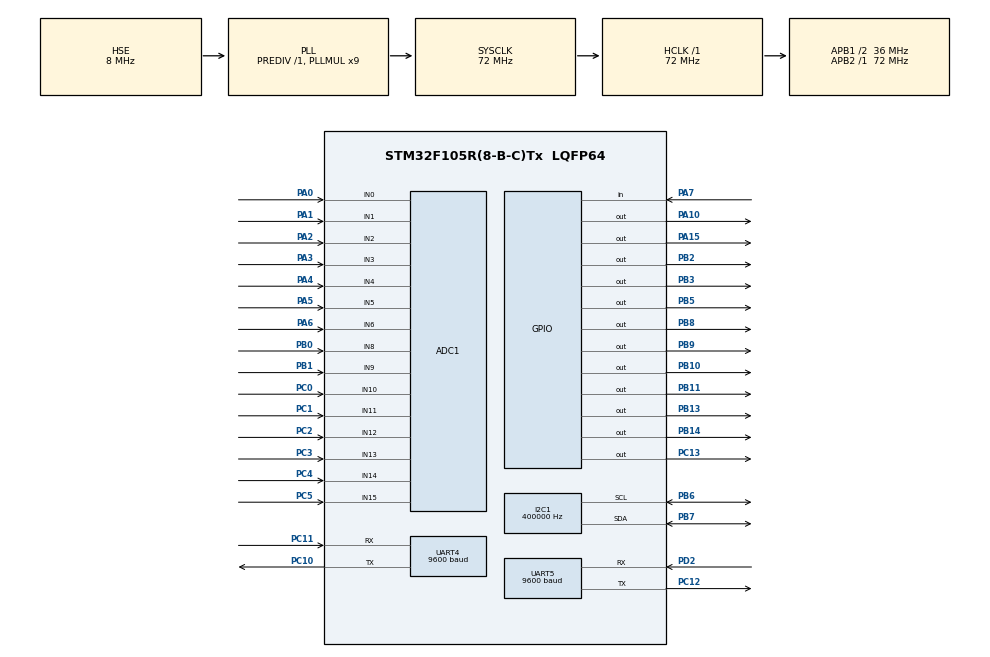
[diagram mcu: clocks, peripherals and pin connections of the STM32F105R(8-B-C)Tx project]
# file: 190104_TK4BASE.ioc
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ADC1.Channel-0\#ChannelRegularConversion=ADC_CHANNEL_0
ADC1.Channel-1\#ChannelRegularConversion=ADC_CHANNEL_1
ADC1.Channel-2\#ChannelRegularConversion=ADC_CHANNEL_2
ADC1.Channel-3\#ChannelRegularConversion=ADC_CHANNEL_3
ADC1.Channel-4\#ChannelRegularConversion=ADC_CHANNEL_4
ADC1.Channel-5\#ChannelRegularConversion=ADC_CHANNEL_5
ADC1.InjNumberOfConversion=0
ADC1.NbrOfConversion=6
ADC1.NbrOfConversionFlag=1
ADC1.Rank-0\#ChannelRegularConversion=1
ADC1.Rank-1\#ChannelRegularConversion=2
ADC1.Rank-2\#ChannelRegularConversion=3
ADC1.Rank-3\#ChannelRegularConversion=4
ADC1.Rank-4\#ChannelRegularConversion=5
ADC1.Rank-5\#ChannelRegularConversion=6
ADC1.SamplingTime-0\#ChannelRegularConversion=ADC_SAMPLETIME_1CYCLE_5
ADC1.SamplingTime-1\#ChannelRegularConversion=ADC_SAMPLETIME_1CYCLE_5
ADC1.SamplingTime-2\#ChannelRegularConversion=ADC_SAMPLETIME_1CYCLE_5
ADC1.SamplingTime-3\#ChannelRegularConversion=ADC_SAMPLETIME_1CYCLE_5
ADC1.SamplingTime-4\#ChannelRegularConversion=ADC_SAMPLETIME_1CYCLE_5
ADC1.SamplingTime-5\#ChannelRegularConversion=ADC_SAMPLETIME_1CYCLE_5
ADC1.master=1
Dma.ADC1.0.Direction=DMA_PERIPH_TO_MEMORY
Dma.ADC1.0.Instance=DMA1_Channel1
Dma.ADC1.0.MemDataAlignment=DMA_MDATAALIGN_HALFWORD
Dma.ADC1.0.MemInc=DMA_MINC_ENABLE
Dma.ADC1.0.Mode=DMA_NORMAL
Dma.ADC1.0.PeriphDataAlignment=DMA_PDATAALIGN_HALFWORD
Dma.ADC1.0.PeriphInc=DMA_PINC_DISABLE
Dma.ADC1.0.Priority=DMA_PRIORITY_LOW
Dma.Request0=ADC1
I2C1.ClockSpeed=400000
I2C1.I2C_Mode=I2C_Fast
Mcu.Family=STM32F1
Mcu.Name=STM32F105R(8-B-C)Tx
Mcu.Package=LQFP64
NVIC.DMA1_Channel1_IRQn=true\:0\:0\:false\:false\:true\:false
NVIC.PriorityGroup=NVIC_PRIORITYGROUP_4
NVIC.TIM6_IRQn=true\:0\:0\:false\:false\:true\:true
NVIC.TIM7_IRQn=true\:0\:0\:false\:false\:true\:true
NVIC.UART4_IRQn=true\:0\:0\:false\:false\:true\:true
NVIC.UART5_IRQn=true\:0\:0\:false\:false\:true\:true
PA0-WKUP.Signal=ADCx_IN0
PA1.Signal=ADCx_IN1
PA10.GPIO_ModeDefaultOutputPP=GPIO_MODE_OUTPUT_PP
PA10.GPIO_Speed=GPIO_SPEED_FREQ_LOW
PA10.PinState=GPIO_PIN_RESET
PA10.Signal=GPIO_Output
PA13.Mode=Serial_Wire
PA13.Signal=SYS_JTMS-SWDIO
PA14.Mode=Serial_Wire
PA14.Signal=SYS_JTCK-SWCLK
PA15.Signal=GPIO_Output
PA2.Signal=ADCx_IN2
PA3.Signal=ADCx_IN3
PA4.Signal=ADCx_IN4
PA5.Signal=ADCx_IN5
PA6.Signal=ADCx_IN6
PA7.Signal=GPIO_Input
PB0.Signal=ADCx_IN8
PB1.Signal=ADCx_IN9
PB10.GPIO_ModeDefaultOutputPP=GPIO_MODE_OUTPUT_PP
PB10.GPIO_Speed=GPIO_SPEED_FREQ_LOW
PB10.PinState=GPIO_PIN_RESET
PB10.Signal=GPIO_Output
PB11.GPIO_ModeDefaultOutputPP=GPIO_MODE_OUTPUT_PP
PB11.GPIO_Speed=GPIO_SPEED_FREQ_LOW
PB11.PinState=GPIO_PIN_RESET
PB11.Signal=GPIO_Output
PB13.Signal=GPIO_Output
PB14.Signal=GPIO_Output
PB2.GPIO_ModeDefaultOutputPP=GPIO_MODE_OUTPUT_PP
PB2.GPIO_Speed=GPIO_SPEED_FREQ_LOW
PB2.PinState=GPIO_PIN_RESET
PB2.Signal=GPIO_Output
PB3.Signal=GPIO_Output
PB5.Signal=GPIO_Output
PB6.GPIO_Mode=GPIO_MODE_AF_OD
PB6.GPIO_Speed=GPIO_SPEED_FREQ_HIGH
PB6.Mode=I2C
PB6.Signal=I2C1_SCL
PB7.GPIO_Mode=GPIO_MODE_AF_OD
PB7.GPIO_Speed=GPIO_SPEED_FREQ_HIGH
PB7.Mode=I2C
PB7.Signal=I2C1_SDA
PB8.Signal=GPIO_Output
PB9.Signal=GPIO_Output
PC0.Signal=ADCx_IN10
PC1.Signal=ADCx_IN11
PC10.Mode=Asynchronous
PC10.Signal=UART4_TX
PC11.Mode=Asynchronous
PC11.Signal=UART4_RX
PC12.Mode=Asynchronous
PC12.Signal=UART5_TX
PC13-TAMPER-RTC.GPIO_ModeDefaultOutputPP=GPIO_MODE_OUTPUT_PP
PC13-TAMPER-RTC.GPIO_Speed=GPIO_SPEED_FREQ_LOW
PC13-TAMPER-RTC.PinState=GPIO_PIN_RESET
PC13-TAMPER-RTC.Signal=GPIO_Output
PC14-OSC32_IN.Mode=LSE-External-Oscillator
PC14-OSC32_IN.Signal=RCC_OSC32_IN
PC15-OSC32_OUT.Mode=LSE-External-Oscillator
PC15-OSC32_OUT.Signal=RCC_OSC32_OUT
PC2.Signal=ADCx_IN12
PC3.Signal=ADCx_IN13
PC4.Signal=ADCx_IN14
PC5.Signal=ADCx_IN15
PD0-OSC_IN.Mode=HSE-External-Oscillator
PD0-OSC_IN.Signal=RCC_OSC_IN
PD1-OSC_OUT.Mode=HSE-External-Oscillator
PD1-OSC_OUT.Signal=RCC_OSC_OUT
PD2.Mode=Asynchronous
PD2.Signal=UART5_RX
ProjectManager.HeapSize=0x200
ProjectManager.StackSize=0x400
ProjectManager.TargetToolchain=SW4STM32
RCC.ADCPresc=RCC_ADCPCLK2_DIV6
RCC.AHBFreq_Value=72000000
RCC.APB1CLKDivider=RCC_HCLK_DIV2
RCC.APB1Freq_Value=36000000
RCC.APB1TimFreq_Value=72000000
RCC.APB2Freq_Value=72000000
RCC.APB2TimFreq_Value=72000000
RCC.HCLKFreq_Value=72000000
RCC.PLL2Mul=RCC_PLL2_MUL10
RCC.PLLMUL=RCC_PLL_MUL9
RCC.PLLSourceVirtual=RCC_PLLSOURCE_HSE
RCC.Prediv2=RCC_HSE_PREDIV2_DIV2
RCC.RTCClockSelection=RCC_RTCCLKSOURCE_LSE
RCC.SYSCLKFreq_VALUE=72000000
RCC.SYSCLKSource=RCC_SYSCLKSOURCE_PLLCLK
RCC.USBFreq_Value=48000000
SH.ADCx_IN0.0=ADC1_IN0,IN0
SH.ADCx_IN1.0=ADC1_IN1,IN1
SH.ADCx_IN10.0=ADC1_IN10,IN10
SH.ADCx_IN11.0=ADC1_IN11,IN11
SH.ADCx_IN12.0=ADC1_IN12,IN12
SH.ADCx_IN13.0=ADC1_IN13,IN13
SH.ADCx_IN14.0=ADC1_IN14,IN14
SH.ADCx_IN15.0=ADC1_IN15,IN15
SH.ADCx_IN2.0=ADC1_IN2,IN2
SH.ADCx_IN3.0=ADC1_IN3,IN3
SH.ADCx_IN4.0=ADC1_IN4,IN4
SH.ADCx_IN5.0=ADC1_IN5,IN5
SH.ADCx_IN6.0=ADC1_IN6,IN6
SH.ADCx_IN8.0=ADC1_IN8,IN8
SH.ADCx_IN9.0=ADC1_IN9,IN9
TIM6.Prescaler=7200-1
TIM7.Prescaler=7200-1
UART4.BaudRate=9600
UART4.VirtualMode=Asynchronous
UART4.WordLength=WORDLENGTH_8B
UART5.BaudRate=9600
UART5.VirtualMode=Asynchronous
UART5.WordLength=WORDLENGTH_8B
VP_CRC_VS_CRC.Mode=CRC_Activate
VP_IWDG_VS_IWDG.Mode=IWDG_Activate
VP_RTC_VS_RTC_Activate.Mode=RTC_Enabled
VP_RTC_VS_RTC_Calendar.Mode=RTC_Calendar
VP_TIM6_VS_ClockSourceINT.Mode=Enable_Timer
VP_TIM7_VS_ClockSourceINT.Mode=Enable_Timer
board=171108_test

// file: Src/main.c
/* USER CODE BEGIN Header */
/**
  ******************************************************************************
  * @file           : main.c
  * @brief          : Main program body
  ******************************************************************************
  ** This notice applies to any and all portions of this file
  * that are not between comment pairs USER CODE BEGIN and
  * USER CODE END. Other portions of this file, whether
  * inserted by the user or by software development tools
  * are owned by their respective copyright owners.
  *
  * COPYRIGHT(c) 2019 STMicroelectronics
  *
  * Redistribution and use in source and binary forms, with or without modification,
  * are permitted provided that the following conditions are met:
  *   1. Redistributions of source code must retain the above copyright notice,
  *      this list of conditions and the following disclaimer.
  *   2. Redistributions in binary form must reproduce the above copyright notice,
  *      this list of conditions and the following disclaimer in the documentation
  *      and/or other materials provided with the distribution.
  *   3. Neither the name of STMicroelectronics nor the names of its contributors
  *      may be used to endorse or promote products derived from this software
  *      without specific prior written permission.
  *
  * THIS SOFTWARE IS PROVIDED BY THE COPYRIGHT HOLDERS AND CONTRIBUTORS "AS IS"
  * AND ANY EXPRESS OR IMPLIED WARRANTIES, INCLUDING, BUT NOT LIMITED TO, THE
  * IMPLIED WARRANTIES OF MERCHANTABILITY AND FITNESS FOR A PARTICULAR PURPOSE ARE
  * DISCLAIMED. IN NO EVENT SHALL THE COPYRIGHT HOLDER OR CONTRIBUTORS BE LIABLE
  * FOR ANY DIRECT, INDIRECT, INCIDENTAL, SPECIAL, EXEMPLARY, OR CONSEQUENTIAL
  * DAMAGES (INCLUDING, BUT NOT LIMITED TO, PROCUREMENT OF SUBSTITUTE GOODS OR
  * SERVICES; LOSS OF USE, DATA, OR PROFITS; OR BUSINESS INTERRUPTION) HOWEVER
  * CAUSED AND ON ANY THEORY OF LIABILITY, WHETHER IN CONTRACT, STRICT LIABILITY,
  * OR TORT (INCLUDING NEGLIGENCE OR OTHERWISE) ARISING IN ANY WAY OUT OF THE USE
  * OF THIS SOFTWARE, EVEN IF ADVISED OF THE POSSIBILITY OF SUCH DAMAGE.
  *
  ******************************************************************************
  */
/* USER CODE END Header */

#include "main.h"
#include "adc.h"
#include "crc.h"
#include "dma.h"
#include "i2c.h"
#include "iwdg.h"
#include "rtc.h"
#include "tim.h"
#include "usart.h"
#include "gpio.h"

/* USER CODE BEGIN Includes */
#include "tkMain.h"
/* USER CODE END Includes */

volatile tkMAIN_status_t tk_STATUS = tkMAIN_UNKNOWN_Err;
/* USER CODE BEGIN PV */
/* Private variables ---------------------------------------------------------*/

/* USER CODE END PV */

void SystemClock_Config(void);
/* USER CODE BEGIN PFP */
/* Private function prototypes -----------------------------------------------*/

/* USER CODE END PFP */

int main(void)
{

  /* MCU Configuration--------------------------------------------------------*/

  /* Reset of all peripherals, Initializes the Flash interface and the Systick. */
  HAL_Init();

  /* Configure the system clock */
  SystemClock_Config();

  /* Initialize all configured peripherals */
  MX_GPIO_Init();
  MX_DMA_Init();
  MX_I2C1_Init();
  MX_ADC1_Init();
  MX_CRC_Init();
  MX_RTC_Init();
  MX_UART4_Init();
  MX_UART5_Init();
  MX_TIM6_Init();
  MX_TIM7_Init();
//  MX_IWDG_Init();
  /* USER CODE BEGIN 2 */
//  HAL_TIM_Base_Start(&htim6);		/* Запустити таймер 				*/
//  HAL_TIM_Base_Start(&htim7);
//  HAL_TIM_Base_Start_IT(&htim6);	/* Запустити переривання по таймеру */
//  HAL_TIM_Base_Start_IT(&htim7);
//  HAL_TIM_Base_Stop_IT(&htim7);		/* Зупинити переривання по таймеру 	*/
//  HAL_TIM_Base_Stop(&htim7);		/* Зупинити таймер					*/
  /* USER CODE END 2 */

  /* Infinite loop */
  /* USER CODE BEGIN WHILE */
  if (tkInit() != tkMAIN_OK){
//	  f_PutErrRecord(ERR tkI);
	  Error_Handler();
  }
  while (1) {
	  if (tkLoop() != tkMAIN_OK){
	 	  Error_Handler();
	  };

    /* USER CODE END WHILE */

  }
}

void SystemClock_Config(void)
{
  RCC_OscInitTypeDef RCC_OscInitStruct = {0};
  RCC_ClkInitTypeDef RCC_ClkInitStruct = {0};
  RCC_PeriphCLKInitTypeDef PeriphClkInit = {0};

  /**Initializes the CPU, AHB and APB busses clocks
  */
  RCC_OscInitStruct.OscillatorType = RCC_OSCILLATORTYPE_LSI|RCC_OSCILLATORTYPE_HSE;
  RCC_OscInitStruct.HSEState = RCC_HSE_ON;
  RCC_OscInitStruct.HSEPredivValue = RCC_HSE_PREDIV_DIV1;
  RCC_OscInitStruct.HSIState = RCC_HSI_ON;
  RCC_OscInitStruct.LSIState = RCC_LSI_ON;
  RCC_OscInitStruct.Prediv1Source = RCC_PREDIV1_SOURCE_HSE;
  RCC_OscInitStruct.PLL.PLLState = RCC_PLL_ON;
  RCC_OscInitStruct.PLL.PLLSource = RCC_PLLSOURCE_HSE;
  RCC_OscInitStruct.PLL.PLLMUL = RCC_PLL_MUL9;
  RCC_OscInitStruct.PLL2.PLL2State = RCC_PLL_NONE;
  if (HAL_RCC_OscConfig(&RCC_OscInitStruct) != HAL_OK)
  {
    Error_Handler();
  }
  /**Initializes the CPU, AHB and APB busses clocks
  */
  RCC_ClkInitStruct.ClockType = RCC_CLOCKTYPE_HCLK|RCC_CLOCKTYPE_SYSCLK
                              |RCC_CLOCKTYPE_PCLK1|RCC_CLOCKTYPE_PCLK2;
  RCC_ClkInitStruct.SYSCLKSource = RCC_SYSCLKSOURCE_PLLCLK;
  RCC_ClkInitStruct.AHBCLKDivider = RCC_SYSCLK_DIV1;
  RCC_ClkInitStruct.APB1CLKDivider = RCC_HCLK_DIV2;
  RCC_ClkInitStruct.APB2CLKDivider = RCC_HCLK_DIV1;

  if (HAL_RCC_ClockConfig(&RCC_ClkInitStruct, FLASH_LATENCY_2) != HAL_OK)
  {
    Error_Handler();
  }
  PeriphClkInit.PeriphClockSelection = RCC_PERIPHCLK_RTC|RCC_PERIPHCLK_ADC;
  PeriphClkInit.RTCClockSelection = RCC_RTCCLKSOURCE_LSI;
  PeriphClkInit.AdcClockSelection = RCC_ADCPCLK2_DIV6;
  if (HAL_RCCEx_PeriphCLKConfig(&PeriphClkInit) != HAL_OK)
  {
    Error_Handler();
  }
  /**Configure the Systick interrupt time
  */
  __HAL_RCC_PLLI2S_ENABLE();
}

void Error_Handler(void)
{
  /* USER CODE BEGIN Error_Handler_Debug */

  /* User can add his own implementation to report the HAL error return state */
  while(tk_STATUS)
  {
  }
  /* USER CODE END Error_Handler_Debug */
}

/************************ (C) COPYRIGHT STMicroelectronics *****END OF FILE****/
